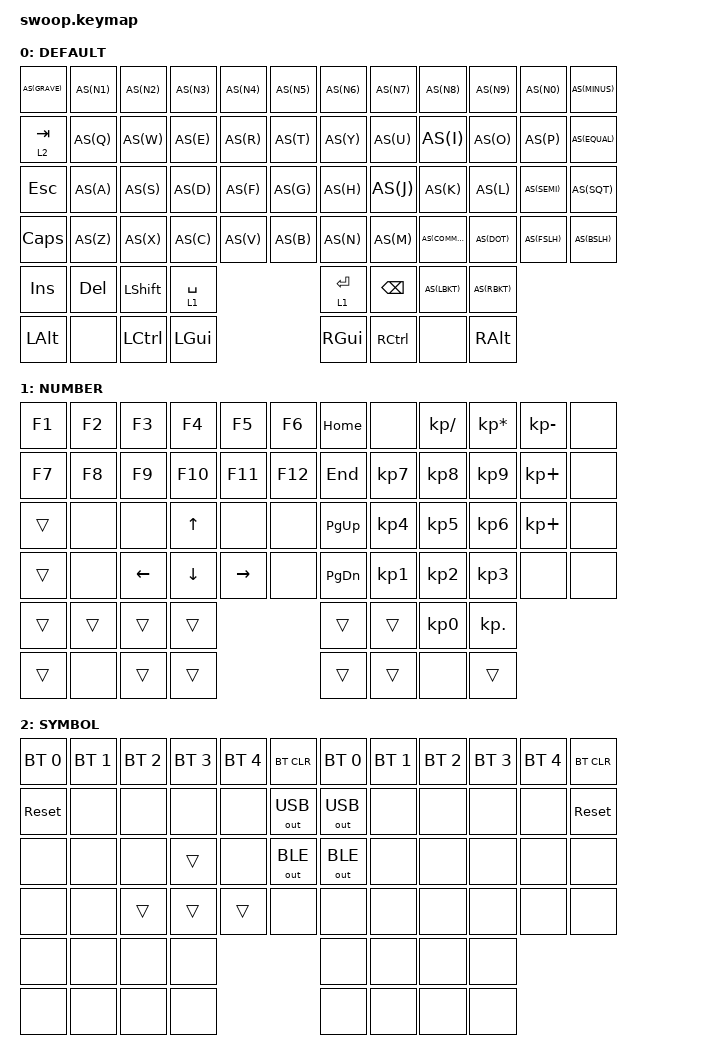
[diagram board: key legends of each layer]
/*
 * Copyright (c) 2020 duckyb
 *
 * SPDX-License-Identifier: MIT
 */

#include <behaviors.dtsi>
#include <dt-bindings/zmk/keys.h>
#include <dt-bindings/zmk/rgb.h>
#include <dt-bindings/zmk/bt.h>
#include <dt-bindings/zmk/outputs.h>


#define DEFAULT 0
#define NUMBER  1
#define SYMBOL  2
#define HOTKEY  3

#define AS(keycode) &as LS(keycode) keycode




/ {
        behaviors {
            td0: tap_dance_0 {
                compatible = "zmk,behavior-tap-dance";
                label = "TAP_DANCE_0";
                #binding-cells = <0>;
                tapping-term-ms = <200>;
                bindings = <&kp ESC>, <&kp TAB>;
            };
        };  
        behaviors {
            as: auto_shift {
                compatible = "zmk,behavior-hold-tap";
                label = "AUTO_SHIFT";
                #binding-cells = <2>;
                tapping-term-ms = <200>;
                quick-tap-ms = <0>;
                flavor = "tap-preferred";
                bindings = <&kp>, <&kp>;
            };             
            modcp: mod_copy {
                compatible = "zmk,behavior-mod-morph";
                label = "MOD_COPY";
                #binding-cells = <0>;
                bindings = <&as LS(C) C>, <&kp C>;
                mods = <(LGUI | RGUI)>;
            };
        };


    macros {
        macro_phone: macro_phone {
            // 1351
            label = "MACRO_PHONE";
            compatible = "zmk,behavior-macro";
            #binding-cells = <0>;
            bindings
                = < &kp N1 &kp N3 &kp N5  &kp N1>
                ;
        };
        macro_email_q: macro_email_q {
            // 2894512440@qq.com
            label = "MACRO_EMAIL_QQ";
            compatible = "zmk,behavior-macro";
            #binding-cells = <0>;
            bindings 
                = < &kp N2 &kp N8 &kp N9 &kp N4 &kp N5 &kp  N1 &kp N2 &kp N4 &kp N4 &kp N0 
                    &kp AT &kp Q &kp Q &kp DOT  &kp C &kp O &kp M>
                ;
        };
        macro_email_g: macro_email_g {
            // 135115
            compatible = "zmk,behavior-macro";
            label = "MACRO_EMAIL_GMAIL";
            #binding-cells = <0>;
            bindings
                = < &kp N1 &kp N3 &kp N5  &kp N1 &kp N1 &kp N5 > ;
        };
       
    };

    keymap {
       compatible = "zmk,keymap";
       default_layer {
            label = "DEFAULT";
            bindings = <
                AS(GRAVE) AS(N1)   AS(N2)    AS(N3)  AS(N4)  AS(N5)          AS(N6)      AS(N7)    AS(N8)    AS(N9)   AS(N0)   AS(MINUS)
                &lt 2 TAB AS(Q)    AS(W)     AS(E)   AS(R)   AS(T)           AS(Y)       AS(U)     AS(I)     AS(O)    AS(P)    AS(EQUAL)
                &kp ESC   AS(A)    AS(S)     AS(D)   AS(F)   AS(G)           AS(H)       AS(J)     AS(K)     AS(L)    AS(SEMI) AS(SQT)
                &kp CAPS AS(Z)    AS(X)     AS(C)   AS(V)   AS(B)           AS(N)       AS(M)     AS(COMMA) AS(DOT)  AS(FSLH) AS(BSLH)  
                &kp INS  &kp DEL  &kp LSHFT  &lt 1 SPACE                      &lt 1 ENTER &kp BSPC  AS(LBKT)  AS(RBKT)          
                &kp LALT  &none	   &kp LCTRL &kp LGUI 	                     &kp RGUI    &kp RCTRL &none     &kp RALT

            >;
        };
        number_layer {
            label = "NUMBER";
            bindings = <
                &kp F1   &kp F2 &kp F3      &kp F4    &kp F5       &kp F6          &kp HOME &none     &kp KP_SLASH &kp KP_MULTIPLY   &kp KP_MINUS &none
                &kp F7   &kp F8 &kp F9      &kp F10   &kp F11      &kp F12         &kp END  &kp KP_N7 &kp KP_N8    &kp KP_N9         &kp KP_PLUS  &none 
                &trans   &none  &none       &kp UP    &none        &none           &kp PG_UP  &kp KP_N4 &kp KP_N5    &kp KP_N6         &kp KP_PLUS  &none
                &trans   &none  &kp LEFT    &kp DOWN  &kp RIGHT    &none           &kp PG_DN  &kp KP_N1 &kp KP_N2    &kp KP_N3         &none        &none 
                &trans   &trans &trans      &trans                                 &trans &trans	&kp KP_N0    &kp KP_DOT	
                &trans   &none  &trans      &trans                                 &trans &trans    &none        &trans     	

            >;
        };

        symbol_layer {
            label = "SYMBOL";
            bindings = <
                &bt BT_SEL 0	&bt BT_SEL 1	&bt BT_SEL 2	&bt BT_SEL 3 &bt BT_SEL 4 &bt BT_CLR 	&bt BT_SEL 0	&bt BT_SEL 1	&bt BT_SEL 2	&bt BT_SEL 3 &bt BT_SEL 4 &bt BT_CLR 
                &sys_reset 	&none	&none	&none	&none	&out OUT_USB	&out OUT_USB	&none	&none	&none	&none	&sys_reset 
                &none	&none	&none	&trans	&none	&out OUT_BLE	&out OUT_BLE	&none	&none	&none	&none	&none
	            &none	&none	&trans	&trans	&trans	&none	&none	&none	&none	&none	&none	&none
		        &none	&none 	&none	&none	&none	&none	&none	&none		
		        &none	&none	&none	&none	&none	&none	&none	&none	                                                        
            >;
        };
   };
};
